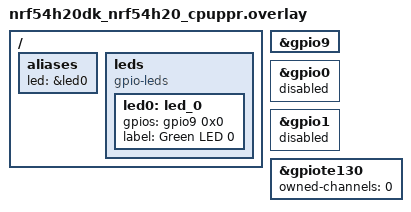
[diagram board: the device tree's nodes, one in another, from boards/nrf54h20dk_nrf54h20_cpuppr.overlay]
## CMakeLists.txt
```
#
# Copyright (c) 2024 Nordic Semiconductor ASA
#
# SPDX-License-Identifier: LicenseRef-Nordic-5-Clause
#

cmake_minimum_required(VERSION 3.20.0)

find_package(Zephyr REQUIRED HINTS $ENV{ZEPHYR_BASE})

if(NOT SYSBUILD)
  message(FATAL_ERROR
    " This is a multi-image application that should be built using sysbuild.\n"
    " Add --sysbuild argument to west build command to prepare all the images.")
endif()

project(idle_twim)

target_sources(app PRIVATE src/main.c)
```

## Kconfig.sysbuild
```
#
# Copyright (c) 2025 Nordic Semiconductor ASA
#
# SPDX-License-Identifier: LicenseRef-Nordic-5-Clause
#

source "share/sysbuild/Kconfig"

choice NETCORE
	default NETCORE_REMOTE_SLEEP_FOREVER

config NETCORE_REMOTE_SLEEP_FOREVER
	bool "Remote sleep forever image"

endchoice

config NETCORE_IMAGE_NAME
	default "remote_sleep_forever" if NETCORE_REMOTE_SLEEP_FOREVER

config NETCORE_IMAGE_PATH
	default "${ZEPHYR_NRF_MODULE_DIR}/tests/benchmarks/power_consumption/common/remote_sleep_forever" if NETCORE_REMOTE_SLEEP_FOREVER

config SUPPORT_NETCORE
	default y if (SOC_NRF54H20_CPUPPR || SOC_NRF54H20_CPUAPP)

config NETCORE_REMOTE_BOARD_TARGET_CPUCLUSTER
	default "cpurad" if (SOC_NRF54H20_CPUPPR || SOC_NRF54H20_CPUAPP)
```

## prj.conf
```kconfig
CONFIG_I2C=y
CONFIG_GPIO=y

CONFIG_BOOT_BANNER=n
CONFIG_NCS_BOOT_BANNER=n
CONFIG_ASSERT=y

# Enable for debugging purposes only
CONFIG_PRINTK=n
CONFIG_LOG=n
CONFIG_CONSOLE=n
CONFIG_UART_CONSOLE=n
CONFIG_SERIAL=n
```

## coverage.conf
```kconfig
CONFIG_I2C=y
CONFIG_GPIO=y

CONFIG_PM=y
CONFIG_PM_DEVICE=y
CONFIG_PM_DEVICE_RUNTIME=y
CONFIG_POWEROFF=y

CONFIG_BOOT_BANNER=n
CONFIG_NCS_BOOT_BANNER=n
CONFIG_ASSERT=n
CONFIG_CLOCK_CONTROL=n

CONFIG_PRINTK=y
CONFIG_LOG=n
CONFIG_CONSOLE=y
CONFIG_UART_CONSOLE=y

CONFIG_LOG_BUFFER_SIZE=16384
```

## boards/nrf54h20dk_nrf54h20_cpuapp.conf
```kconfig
CONFIG_PM_S2RAM=y
CONFIG_PM_S2RAM_CUSTOM_MARKING=y

CONFIG_SOC_NRF54H20_CPURAD_ENABLE=y
```

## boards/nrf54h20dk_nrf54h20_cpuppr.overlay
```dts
/ {
	aliases {
		led = &led0;
	};

	leds {
		compatible = "gpio-leds";

		led0: led_0 {
			gpios = <&gpio9 0x0 0x0>;
			label = "Green LED 0";
		};
	};
};

&gpio9 {
	status = "okay";
};

&gpio0 {
	status = "disabled";
};

&gpio1 {
	status = "disabled";
};

&gpiote130 {
	status = "okay";
	owned-channels = <0>;
};
```

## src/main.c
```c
/*
 * Copyright (c) 2024 Nordic Semiconductor ASA
 *
 * SPDX-License-Identifier: LicenseRef-Nordic-5-Clause
 */

#include <zephyr/kernel.h>
#include <zephyr/logging/log.h>
#include <zephyr/drivers/i2c.h>
#include <zephyr/drivers/gpio.h>

/* Note: logging is normally disabled for this test
 * Enable only for debugging purposes
 */
LOG_MODULE_REGISTER(idle_twim);

#define SENSOR_NODE    DT_COMPAT_GET_ANY_STATUS_OKAY(bosch_bme680)
#define I2C_TEST_NODE  DT_PARENT(SENSOR_NODE)
#define DEVICE_ADDRESS (uint8_t) DT_REG_ADDR(SENSOR_NODE)

#define CHIP_ID_REGISTER_ADDRESS    0xD0
#define VARIANT_ID_REGISTER_ADDRESS 0xF0
#define TWIM_READ_COUNT		    10

static const struct device *const i2c_device = DEVICE_DT_GET(I2C_TEST_NODE);
static const struct gpio_dt_spec led = GPIO_DT_SPEC_GET(DT_ALIAS(led), gpios);

/*
 * Helper method for reading the BME688 I2C registers
 */
static uint8_t read_sensor_register(uint8_t register_address)
{
	int rc;
	uint8_t response;

	rc = i2c_reg_read_byte(i2c_device, DEVICE_ADDRESS, register_address, &response);
	__ASSERT_NO_MSG(rc == 0);
	printk("I2C read reg, addr: 0x%x, val: 0x%x\n", register_address, response);
	return response;
}

int main(void)
{
	uint8_t response;
	int test_repetitions = 3;
	uint32_t i2c_config = I2C_SPEED_SET(I2C_SPEED_STANDARD) | I2C_MODE_CONTROLLER;

	response = gpio_is_ready_dt(&led);
	__ASSERT(response, "Error: GPIO Device not ready");

	response = gpio_pin_configure_dt(&led, GPIO_OUTPUT_ACTIVE);
	__ASSERT(response == 0, "Could not configure led GPIO");

	printk("Device address 0x%x\n", DEVICE_ADDRESS);
	printk("I2C speed setting: %d\n", I2C_SPEED_STANDARD);

	response = i2c_configure(i2c_device, i2c_config);
	if (response != 0) {
		printk("I2C configuration failed%d\n", response);
		__ASSERT_NO_MSG(response == 0);
	}

#if defined(CONFIG_COVERAGE)
	printk("Coverage analysis enabled\n");
	while (test_repetitions--)
#else
	while (test_repetitions)
#endif
	{
		for (int read_index = 0; read_index < TWIM_READ_COUNT; read_index++) {
			response = read_sensor_register(CHIP_ID_REGISTER_ADDRESS);
			printk("Chip_Id: %d\n", response);
			__ASSERT_NO_MSG(response != 0);
			response = read_sensor_register(VARIANT_ID_REGISTER_ADDRESS);
			printk("Variant_Id: %d\n", response);
			__ASSERT_NO_MSG(response != 0);
		}

		gpio_pin_set_dt(&led, 0);
		k_msleep(1000);
		gpio_pin_set_dt(&led, 1);
	}

#if defined(CONFIG_COVERAGE)
	printk("Coverage analysis start\n");
#endif
	return 0;
}
```
